# H6 register map
Vendor: Allwinner; Series: H6; File version: 0.1
CPU: CA53 0, little endian, MPU, no FPU, 0 interrupt priority bits
Registers are 32-bit, read-write, reset 0x0 unless marked. A register's access mark holds for its fields unless they carry their own. Offsets are from the block's base; [hi:lo] are bit positions; {n}, {i} and the like mark numbered series.

## EMCE
Base 0x01905000
0x00 EMCE_KEY0 — EMCE Master Key`s 1st Word
  [31:0] EMCE — master key`s 1st word
0x04 EMCE_KEY1 — EMCE Master key`s 2nd Word
  [31:0] EMCE — master key`s 2nd word
0x08 EMCE_KEY2 — EMCE Master Key`s 3rd Word
  [31:0] EMCE — master key`s 3rd word
{0x0+4i} EMCE_KEY{i} (i=3..7) — EMCE Master Key`s {i+1}th Word
  [31:0] EMCE — master key`s {i+1}th word
0x40 EMCE_SALT0 — EMCE Master Salt`s 1st Word
  [31:0] EMCE — salt`s 1st word
0x44 EMCE_SALT1 — EMCE Master Salt`s 2nd Word
  [31:0] EMCE — salt`s 2nd word
0x48 EMCE_SALT2 — EMCE Master Salt`s 3rd Word
  [31:0] EMCE — salt`s 3rd word
{0x40+4i} EMCE_SALT{i} (i=3..7) — EMCE Master Salt`s {i+1}th Word
  [31:0] EMCE — salt`s {i+1}th word
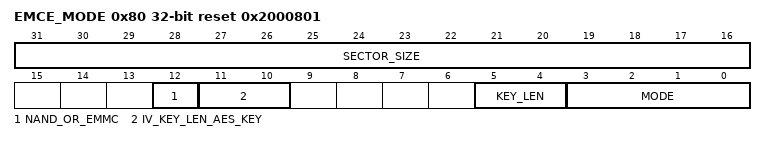
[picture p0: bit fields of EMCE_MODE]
0x80 EMCE_MODE reset 0x2000801 — AES Configuration for Key Length and Mode
  [31:16] SECTOR_SIZE — Sector Size for Controller
  [12] NAND_OR_EMMC — NAND_OR_EMMC 0: current controller is NDFC 1: current controller is SMHC
    0=NDFC (current controller is NDFC); 1=SMHC (current controller is SMHC)
  [11:10] IV_KEY_LEN_AES_KEY — IV_KEY_LEN AES key length when computing IV 00: 128-bit 01: 192-bit 10: 256-bit 11: reserved
    0=_128_bit; 1=_192_bit; 2=_256_bit
  [5:4] KEY_LEN — KEY_LEN 00: 128-bit 01: 192-bit 10: 256-bit 11: reserved
    0=_128_bit; 1=_192_bit; 2=_256_bit
  [3:0] MODE — Mode 0000: ECB 0001: CBC 1001:XTS Others: reserved
    0=ECB; 1=CBC (CBC 1001:XTS Others: reserved)

## ATE_EPHY
Base 0x00006000
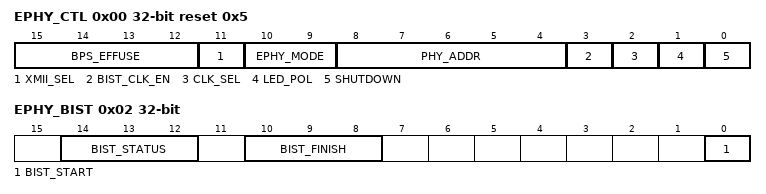
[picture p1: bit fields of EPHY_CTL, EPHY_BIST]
0x00 EPHY_CTL reset 0x5 — Ethernet PHY Control Register
  [15:12] BPS_EFFUSE
  [11] XMII_SEL — 0: MII 1: RMII
    0=MII; 1=RMII
  [10:9] EPHY_MODE — Operation Mode Selection 00 : Normal Mode 01 : Sim Mode 10 : AFE Test Mode 11 : /
  [8:4] PHY_ADDR — PHY Address
  [3] BIST_CLK_EN — 0 : BIST clk disable 1 : BIST clk enable
  [2] CLK_SEL — 0 : 27MHz 1 : 24MHz
  [1] LED_POL — 0 : High active 1 : Low active
  [0] SHUTDOWN — 0 : Power up 1 : Shutdown
0x02 EPHY_BIST — Ethernet PHY BIST Register
  [14:12] BIST_STATUS — bist_status[5]:BIST_FAIL_RMII2MII bist_status[4]:BIST_FAIL_MII2RMII bist_status[3]:BIST_FAIL_PLPIC
  [10:8] BIST_FINISH — bist_status[2]:BIST_FINISH_RMII2MII bist_status[1]:BIST_FINISH_MII2RMII bist_status[0]:BIST_FINISH_PLPIC
  [0] BIST_START — 0 : disable 1 : Start

## High_Speed_Timer
Base 0x03005000
0x00 HS_TMR_IRQ_EN_REG — HS Timer IRQ Enable Register
  [0] HS_TMR0_INT_EN write-1-sets — High Speed Timer 0 Interrupt Enable. 0: No effect 1: High Speed Timer 0 Interval Value reached interrupt enable
    0=No_effect; 1=High Speed Timer 0 Interval Value reached interrupt enable
0x04 HS_TMR_IRQ_STAS_REG — HS Timer Status Register
  [0] HS_TMR0_IRQ_PEND write-1-clears — High Speed Timer 0 IRQ Pending. Setting 1 to the bit will clear it. 0: No effect 1: Pending, High speed timer 0 interval value is reached
    0=No_effect; 1=Pending, High speed timer 0 interval value is reached
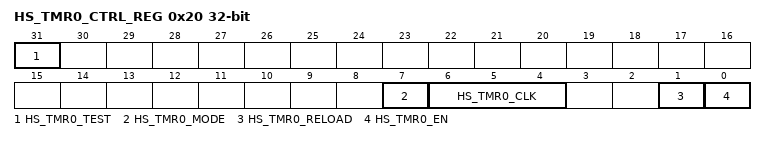
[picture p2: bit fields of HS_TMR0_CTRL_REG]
0x20 HS_TMR0_CTRL_REG — HS Timer 0 Control Register
  [31] HS_TMR0_TEST — High speed timer 0 test mode. In test mode, the low register should be set to 0x1, the high register will down counter. The counter needs to be reloaded. 0: Normal mode 1: Test mode
    0=Normal_mode; 1=Test_mode
  [7] HS_TMR0_MODE — High Speed Timer 0 mode. 0: Continuous mode. When interval value reached, the timer will not disable automatically. 1: Single mode. When interval value reached, the timer will disable automatically.
    0=Continuous mode. When interval value reached, the timer will not disable automatically.; 1=Single mode. When interval value reached, the timer will disable automatically.
  [6:4] HS_TMR0_CLK — Select the pre-scale of the high speed timer 0 clock sources. 000: /1 001: /2 010: /4 011: /8 100: /16 101: / 110: / 111: /
    0=_slash_1 (/1); 1=_slash_2 (/2); 2=_slash_4 (/4); 3=_slash_8 (/8); 4=_slash_16 (/16)
  [1] HS_TMR0_RELOAD write-1-sets — High Speed Timer 0 Reload. 0: No effect 1: Reload High Speed Timer 0 Interval Value
    0=No_effect; 1=Reload High Speed Timer 0 Interval Value
  [0] HS_TMR0_EN — High Speed Timer 0 Enable. 0: Stop/Pause 1: Start If the timer is started, it will reload the interval value to internal register, and the current counter will count from interval value to 0. If the current counter does not reach the zero, the timer enable bit is set to `0`, the current value counter will pause. At least wait for 2 cycles, the start bit can be set to 1. In timer pause state, the interval value register can be modified. If the timer is started again, and the Software hope the current value register to down-count from the new interval value, the reload bit and the enable bit should be set to 1 at the same time.
    0=Stop_slash_Pause (Stop/Pause); 1=Start If the timer is started, it will reload the interval value to internal register, and the current counter will count from interval value to 0. If the current counter does not reach the zero, the timer enable bit is set to `0`, the current value counter will pause. At least wait for 2 cycles, the start bit can be set to 1. In timer pause state, the interval value register can be modified. If the timer is started again, and the Software hope the current value register to down-count from the new interval value, the reload bit and the enable bit should be set to 1 at the same time.
0x24 HS_TMR0_INTV_LO_REG — HS Timer 0 Interval Value Low Register
  [31:0] HS_TMR0_INTV_VALUE_LO — High Speed Timer 0 Interval Value [31:0].
0x28 HS_TMR0_INTV_HI_REG — HS Timer 0 Interval Value High Register
  [23:0] HS_TMR0_INTV_VALUE_HI — High Speed Timer 0 Interval Value [55:32].
0x2C HS_TMR0_CURNT_LO_REG — HS Timer 0 Current Value Low Register
  [31:0] HS_TMR0_CUR_VALUE_LO — High Speed Timer 0 Current Value [31:0].
0x30 HS_TMR0_CURNT_HI_REG — HS Timer 0 Current Value High Register
  [23:0] HS_TMR0_CUR_VALUE_HI — High Speed Timer 0 Current Value [55:32].

## PWM
Base 0x0300A000
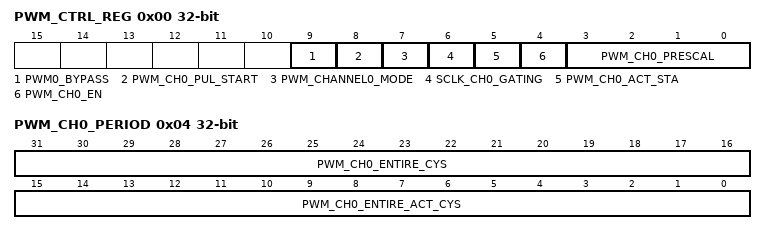
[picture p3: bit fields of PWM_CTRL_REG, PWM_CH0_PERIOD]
0x00 PWM_CTRL_REG — PWM Control Register
  [9] PWM0_BYPASS — PWM channel 0 bypass enable. If the bit is set to 1, PWM0`s output is OSC24MHz. 0: Disable 1: Enable
    0=Disable; 1=Enable
  [8] PWM_CH0_PUL_START — PWM channel 0 pulse output start. 0: No effect 1: Output 1 pulse. The pulse width should be according to the period 0 register[15:0],and the pulse state should be according to the active state. After the pulse is finished,the bit will be cleared automatically.
    0=No_effect; 1=Output 1 pulse. The pulse width should be according to the period 0 register[15:0],and the pulse state should be according to the active state. After the pulse is finished,the bit will be cleared automatically.
  [7] PWM_CHANNEL0_MODE — 0: Cycle mode 1: Pulse mode
    0=Cycle_mode; 1=Pulse_mode
  [6] SCLK_CH0_GATING — Gating the Special Clock for PWM0 0: Mask 1: Pass
    0=Mask; 1=Pass
  [5] PWM_CH0_ACT_STA — PWM channel 0 active state. 0: Low Level 1: High Level
    0=Low_Level; 1=High_Level
  [4] PWM_CH0_EN — PWM channel 0 enable. 0: Disable 1: Enable
    0=Disable; 1=Enable
  [3:0] PWM_CH0_PRESCAL — PWM channel 0 prescalar. These bits should be setting before the PWM channel 0 clock gate on. 0000: /120 0001: /180 0010: /240 0011: /360 0100: /480 0101: / 0110: / 0111: / 1000: /12k 1001: /24k 1010: /36k 1011: /48k 1100: /72k 1101: / 1110: / 1111: /1
    0=_slash_120 (/120); 1=_slash_180 (/180); 2=_slash_240 (/240); 3=_slash_360 (/360); 4=_slash_480 (/480); 8=_slash_12k (/12k); 9=_slash_24k (/24k); 10=_slash_36k (/36k); 11=_slash_48k (/48k); 12=_slash_72k (/72k); 15=_slash_1 (/1)
0x04 PWM_CH0_PERIOD reset not defined — PWM Channel 0 Period Register
  [31:16] PWM_CH0_ENTIRE_CYS — Number of the entire cycles in the PWM clock. 0 : 1 cycle 1: 2 cycles ... N: N+1 cycles If the register need to be modified dynamically, the PCLK should be faster than the PWM CLK(PWM CLK = 24MHz/pre-scale).
  [15:0] PWM_CH0_ENTIRE_ACT_CYS — Number of the active cycles in the PWM clock. 0: 0 cycle 1: 1 cycles ... N : N cycles

## Spinlock
Base 0x03004000
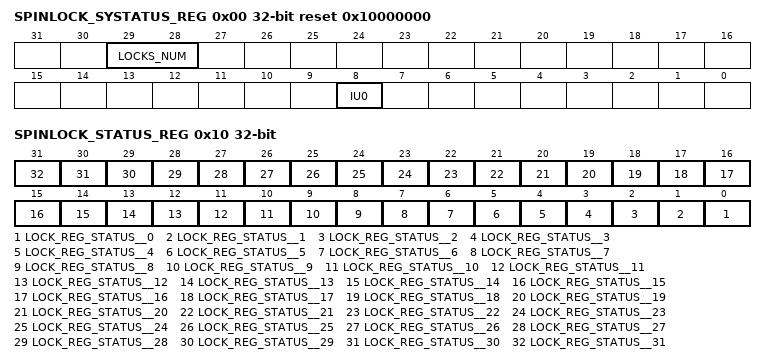
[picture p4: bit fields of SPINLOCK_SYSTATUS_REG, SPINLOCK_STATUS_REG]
0x00 SPINLOCK_SYSTATUS_REG reset 0x10000000 — Spinlock System Status Register
  [29:28] LOCKS_NUM ro — Number of lock registers implemented. 00: This instance has 32 lock registers. 01: This instance has 64 lock registers. 10: This instance has 128 lock registers. 11: This instance has 256 lock registers.
    0=This instance has 32 lock registers; 1=This instance has 64 lock registers; 2=This instance has 128 lock registers; 3=This instance has 256 lock registers
  [8] IU0 ro — In-Use flag0, covering lock register0-31. 0: All lock register 0-31 are in the NotTaken state. 1: At least one of the lock register 0-31 is in the Taken state.
    0=All (All lock register 0-31 are in the NotTaken state.); 1=At (At least one of the lock register 0-31 is in the Taken state.)
0x10 SPINLOCK_STATUS_REG — Spinlock Status Register
  [n] LOCK_REG_STATUS__{n} ro (n=0..31) — SpinLock[i] status (i=0~31) 0: The Spinlock is free 1: The Spinlock is taken.
{0x100+4i} SPINLOCKN_LOCK_REG[{i}] (i=0..31) — SPINLOCKN_LOCK_REG[{i}]
  [0] TAKEN — Lock State. Read 0x0: The lock was previously Not Taken (free).The requester is granted the lock. Write 0x0: Set the lock to Not Taken (free). Read 0x1: The lock was previously Taken. The requester is not granted the lock and must retry. Write 0x1: No update to the lock value.
